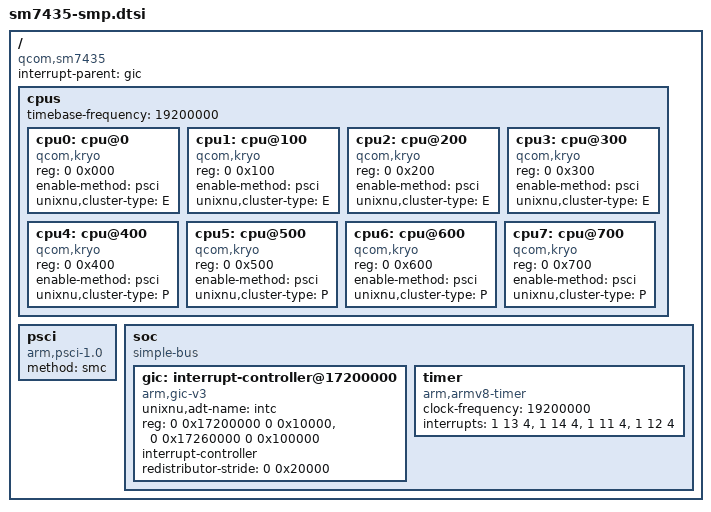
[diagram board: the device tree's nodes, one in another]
// SPDX-License-Identifier: BSD-3-Clause
// SM7435 (Qualcomm Parrot) CPU/SMP bring-up subset for UniXNU.
// Source: LineageOS/android_kernel_xiaomi_sm7435-devicetrees
//         qcom/parrot.dtsi @ 849a8a76b0959f7e7c12eb67081591248b2f8e7b
// Cross-check: this repository's data/dizi-fdt-observed.json (bootloader FDT).
//
// This is a PREPARATORY device description, not evidence of a running XNU SMP.
// Do not add SM8550 registers, power-control writes, storage or GPU modules.
// No DDR ownership / reservation is assumed here.
/ {
    compatible = "qcom,sm7435";
    #address-cells = <2>;
    #size-cells = <2>;
    interrupt-parent = <&gic>;

    cpus {
        #address-cells = <2>;
        #size-cells = <0>;
        timebase-frequency = <19200000>;

        // Vendor Parrot DT identifies all eight logical MPIDRs in Aff1.
        // CPU0..3 are LITTLE; CPU4..7 are BIG according to its cpu-map.
        cpu0: cpu@0 {
            device_type = "cpu";
            compatible = "qcom,kryo";
            reg = <0 0x000>;
            enable-method = "psci";
            unixnu,cluster-type = "E";
        };
        cpu1: cpu@100 {
            device_type = "cpu";
            compatible = "qcom,kryo";
            reg = <0 0x100>;
            enable-method = "psci";
            unixnu,cluster-type = "E";
        };
        cpu2: cpu@200 {
            device_type = "cpu";
            compatible = "qcom,kryo";
            reg = <0 0x200>;
            enable-method = "psci";
            unixnu,cluster-type = "E";
        };
        cpu3: cpu@300 {
            device_type = "cpu";
            compatible = "qcom,kryo";
            reg = <0 0x300>;
            enable-method = "psci";
            unixnu,cluster-type = "E";
        };
        cpu4: cpu@400 {
            device_type = "cpu";
            compatible = "qcom,kryo";
            reg = <0 0x400>;
            enable-method = "psci";
            unixnu,cluster-type = "P";
        };
        cpu5: cpu@500 {
            device_type = "cpu";
            compatible = "qcom,kryo";
            reg = <0 0x500>;
            enable-method = "psci";
            unixnu,cluster-type = "P";
        };
        cpu6: cpu@600 {
            device_type = "cpu";
            compatible = "qcom,kryo";
            reg = <0 0x600>;
            enable-method = "psci";
            unixnu,cluster-type = "P";
        };
        cpu7: cpu@700 {
            device_type = "cpu";
            compatible = "qcom,kryo";
            reg = <0 0x700>;
            enable-method = "psci";
            unixnu,cluster-type = "P";
        };
    };

    psci {
        compatible = "arm,psci-1.0";
        method = "smc";
    };

    soc {
        compatible = "simple-bus";
        #address-cells = <2>;
        #size-cells = <2>;
        ranges;

        // SM7435: 8 redistributor frames, 0x20000 each.
        // Do not copy SM8550's 0x1710.../0x1718... and 0x40000 stride.
        gic: interrupt-controller@17200000 {
            compatible = "arm,gic-v3";
            unixnu,adt-name = "intc";
            reg = <0 0x17200000 0 0x10000>,
                  <0 0x17260000 0 0x100000>;
            #interrupt-cells = <3>;
            interrupt-controller;
            redistributor-stride = <0 0x20000>;
        };

        timer {
            compatible = "arm,armv8-timer";
            clock-frequency = <19200000>;
            // PPI numbers from Qualcomm Parrot DT:
            // virtual timer PPI11 => INTID27.
            interrupts = <1 13 4>, <1 14 4>, <1 11 4>, <1 12 4>;
        };
    };
};
